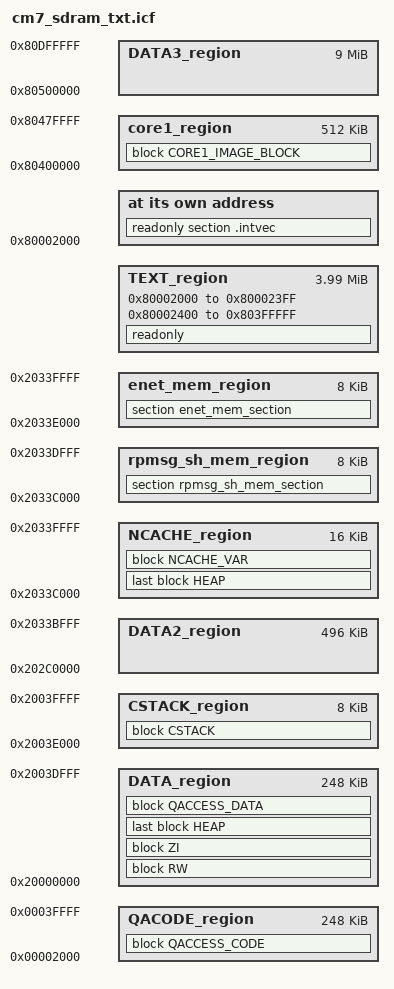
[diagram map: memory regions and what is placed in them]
/*
** ###################################################################
**     Processors:          MIMXRT1176AVM8A_cm7
**                          MIMXRT1176CVM8A_cm7
**                          MIMXRT1176DVMAA_cm7
**
**     Compiler:            IAR ANSI C/C++ Compiler for ARM
**     Reference manual:    IMXRT1170RM, Rev 1, 02/2021
**     Version:             rev. 1.1, 2022-04-02
**     Build:               b220402
**
**     Abstract:
**         Linker file for the IAR ANSI C/C++ Compiler for ARM
**
**     Copyright 2016 Freescale Semiconductor, Inc.
**     Copyright 2016-2022 NXP
**     All rights reserved.
**
**     SPDX-License-Identifier: BSD-3-Clause
**
**     http:                 www.nxp.com
**     mail:                 support@nxp.com
**
** ###################################################################
*/

define symbol m_interrupts_start       = 0x80002000;
define symbol m_interrupts_end         = 0x800023FF;

define symbol m_text_start             = 0x80002400;
define symbol m_text_end               = 0x803FFFFF;

define symbol m_data_start             = 0x20000000;
define symbol m_data_end               = 0x2003FFFF;

define symbol m_data2_start            = 0x202C0000;
define symbol m_data2_end              = 0x2033BFFF;

define exported symbol rpmsg_sh_mem_start      = 0x2033C000;
define exported symbol rpmsg_sh_mem_end        = 0x2033DFFF;

define symbol enet_mem_start = 0x2033E000;
define symbol enet_mem_end = 0x2033FFFF;

define symbol m_data3_start            = 0x80500000;
define symbol m_data3_end              = 0x80DFFFFF;

define exported symbol __SDRAM_HEAP_START = m_data3_start;
define exported symbol __SDRAM_HEAP_SIZE = m_data3_end - m_data3_start + 1;

define symbol m_ncache_start                   = rpmsg_sh_mem_start;
define symbol m_ncache_end                     = enet_mem_end;

define exported symbol __NCACHE_REGION_START   = m_ncache_start;
define exported symbol __NCACHE_REGION_SIZE    = m_ncache_end - m_ncache_start + 1;

define symbol m_qacode_start           = 0x00002000;
define symbol m_qacode_end             = 0x0003FFFF;

define exported symbol core1_image_start     = 0x80400000; //m4_bm bin address
define exported symbol core1_image_end       = 0x8047FFFF; //size 512kB

/* Sizes */
if (isdefinedsymbol(__stack_size__)) {
  define symbol __size_cstack__        = __stack_size__;
} else {
  define symbol __size_cstack__        = 0x2000;
}

if (isdefinedsymbol(__heap_size__)) {
  define symbol __size_heap__          = __heap_size__;
} else {
  define symbol __size_heap__          = 0x2000;
}

define exported symbol __VECTOR_TABLE          = m_interrupts_start;
define exported symbol __VECTOR_RAM            = m_interrupts_start;
define exported symbol __RAM_VECTOR_TABLE_SIZE = 0x0;
define exported symbol __RTT_HEAP_END = m_data2_end;

define memory mem with size = 4G;
define region TEXT_region = mem:[from m_interrupts_start to m_interrupts_end]
                          | mem:[from m_text_start to m_text_end];
define region QACODE_region = mem:[from m_qacode_start to m_qacode_end];
define region DATA_region = mem:[from m_data_start to m_data_end-__size_cstack__];
define region DATA2_region = mem:[from m_data2_start to m_data2_end];
define region DATA3_region  = mem:[from m_data3_start to m_data3_end];
define region CSTACK_region = mem:[from m_data_end-__size_cstack__+1 to m_data_end];
define region NCACHE_region = mem:[from m_ncache_start to m_ncache_end];
define region rpmsg_sh_mem_region = mem:[from rpmsg_sh_mem_start to rpmsg_sh_mem_end];
define region enet_mem_region = mem:[from enet_mem_start to enet_mem_end];

define block CSTACK    with alignment = 8, size = __size_cstack__   { };
define block HEAP      with alignment = 8, size = __size_heap__     { };
define block RW        { first readwrite, section m_usb_dma_init_data };
define block ZI         with alignment = 32  { first zi, section m_usb_dma_noninit_data };
define block NCACHE_VAR    { section NonCacheable , section NonCacheable.init };
define block QACCESS_CODE  { section CodeQuickAccess };
define block QACCESS_DATA  { section DataQuickAccess };
define region core1_region = mem:[from core1_image_start to core1_image_end];
define block CORE1_IMAGE_BLOCK          { section  __core1_image };

initialize by copy { readwrite, section .textrw, section CodeQuickAccess, section DataQuickAccess };
do not initialize  { section .noinit };
do not initialize  { section rpmsg_sh_mem_section };
do not initialize  { section enet_mem_section };

place at address mem: m_interrupts_start    { readonly section .intvec };

place in TEXT_region                        { readonly };
place in DATA_region                       { block RW };
place in DATA_region                       { block ZI };
if (isdefinedsymbol(__heap_noncacheable__)) {
  place in NCACHE_region                    { last block HEAP };
} else {
  place in DATA_region                     { last block HEAP };
}
place in NCACHE_region                      { block NCACHE_VAR };
place in QACODE_region                      { block QACCESS_CODE };
place in DATA_region                        { block QACCESS_DATA };
place in rpmsg_sh_mem_region                { section rpmsg_sh_mem_section };
place in enet_mem_region                    { section enet_mem_section };
place in core1_region                       { block CORE1_IMAGE_BLOCK };
place in CSTACK_region                      { block CSTACK };
